# R9A09G057H register map
Vendor: Renesas Electronics; File version: 1.0
Registers are 32-bit, read-write, no defined reset value unless marked. A register's access mark holds for its fields unless they carry their own. Offsets are from the block's base; [hi:lo] are bit positions; {n}, {i} and the like mark numbered series.

## R_POEGA — IO define file for poeg.
Base 0x13001C00
Same registers: R_POEGB 0x13002000, R_POEGC 0x13002400, R_POEGD 0x13002800, R_POEGE 0x13002C00, R_POEGF 0x13003000, R_POEGG 0x13003400, R_POEGH 0x13003800
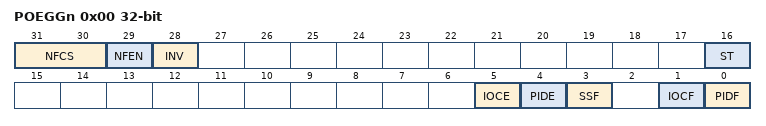
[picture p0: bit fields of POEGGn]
0x00 POEGGn
  [31:30] NFCS, [29] NFEN, [28] INV, [16] ST ro, [5] IOCE, [4] PIDE, [3] SSF, [1] IOCF, [0] PIDF

## R_RIIC0 — IO define file for riic.
Base 0x14400400
Same registers: R_RIIC8 0x11C01000, R_RIIC1 0x14400800, R_RIIC2 0x14400C00, R_RIIC3 0x14401000, R_RIIC4 0x14401400, R_RIIC5 0x14401800, R_RIIC6 0x14401C00, R_RIIC7 0x14402000
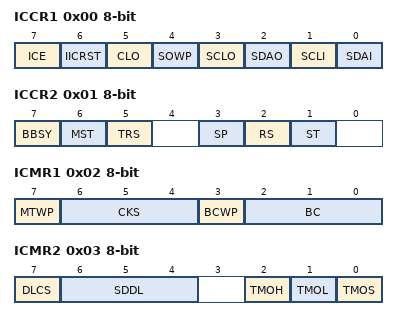
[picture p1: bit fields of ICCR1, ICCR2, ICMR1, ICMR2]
0x00 ICCR1 8-bit
  [7] ICE, [6] IICRST, [5] CLO, [4] SOWP wo, [3] SCLO, [2] SDAO, [1] SCLI ro, [0] SDAI ro
0x01 ICCR2 8-bit
  [7] BBSY ro, [6] MST, [5] TRS, [3] SP, [2] RS, [1] ST
0x02 ICMR1 8-bit
  [7] MTWP, [6:4] CKS, [3] BCWP wo, [2:0] BC
0x03 ICMR2 8-bit
  [7] DLCS, [6:4] SDDL, [2] TMOH, [1] TMOL, [0] TMOS
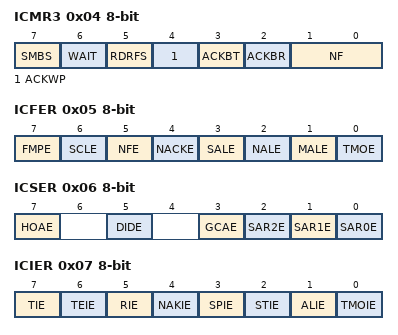
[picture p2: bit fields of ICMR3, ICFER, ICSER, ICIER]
0x04 ICMR3 8-bit
  [7] SMBS, [6] WAIT, [5] RDRFS, [4] ACKWP, [3] ACKBT, [2] ACKBR ro, [1:0] NF
0x05 ICFER 8-bit
  [7] FMPE, [6] SCLE, [5] NFE, [4] NACKE, [3] SALE, [2] NALE, [1] MALE, [0] TMOE
0x06 ICSER 8-bit
  [7] HOAE, [5] DIDE, [3] GCAE, [2] SAR2E, [1] SAR1E, [0] SAR0E
0x07 ICIER 8-bit
  [7] TIE, [6] TEIE, [5] RIE, [4] NAKIE, [3] SPIE, [2] STIE, [1] ALIE, [0] TMOIE
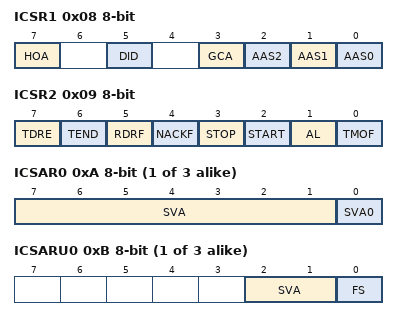
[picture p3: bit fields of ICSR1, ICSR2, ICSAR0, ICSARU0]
0x08 ICSR1 8-bit
  [7] HOA, [5] DID, [3] GCA, [2] AAS2, [1] AAS1, [0] AAS0
0x09 ICSR2 8-bit
  [7] TDRE ro, [6] TEND, [5] RDRF, [4] NACKF, [3] STOP, [2] START, [1] AL, [0] TMOF
{0xA+2i} ICSAR{i} 8-bit (i=0..2)
  [7:1] SVA, [0] SVA0
{0xB+2i} ICSARU{i} 8-bit (i=0..2)
  [2:1] SVA, [0] FS
0x10 ICBRL 8-bit
  [4:0] BRL
0x11 ICBRH 8-bit
  [4:0] BRH
0x12 ICDRT 8-bit
  [7:0] DRT
0x13 ICDRR 8-bit ro
  [7:0] DRR

## R_RTC — IO define file for rtc.
Base 0x11C00800
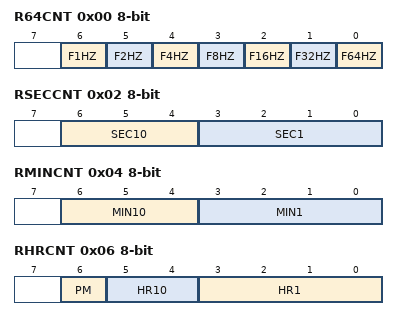
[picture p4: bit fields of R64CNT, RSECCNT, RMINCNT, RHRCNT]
0x00 R64CNT 8-bit ro
  [6] F1HZ, [5] F2HZ, [4] F4HZ, [3] F8HZ, [2] F16HZ, [1] F32HZ, [0] F64HZ
0x02 RSECCNT 8-bit
  [6:4] SEC10, [3:0] SEC1
{0x2+2i} BCNT{i} 8-bit (i=0..3)
  [7:0] BCNT
0x04 RMINCNT 8-bit
  [6:4] MIN10, [3:0] MIN1
0x06 RHRCNT 8-bit
  [6] PM, [5:4] HR10, [3:0] HR1
0x08 RWKCNT 8-bit
  [2:0] DAYW
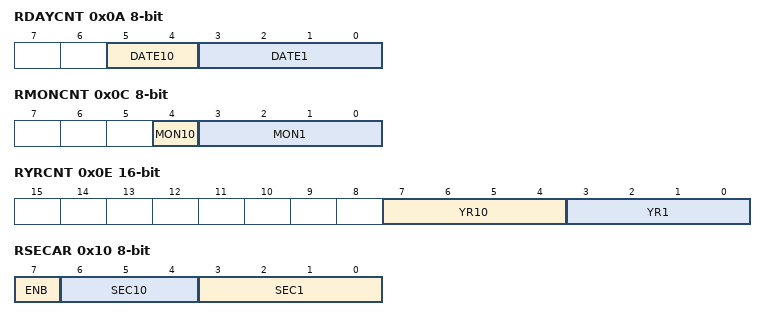
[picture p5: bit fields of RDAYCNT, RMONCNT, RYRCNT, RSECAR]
0x0A RDAYCNT 8-bit
  [5:4] DATE10, [3:0] DATE1
0x0C RMONCNT 8-bit
  [4] MON10, [3:0] MON1
0x0E RYRCNT 16-bit
  [7:4] YR10, [3:0] YR1
0x10 RSECAR 8-bit
  [7] ENB, [6:4] SEC10, [3:0] SEC1
{0x10+2i} BCNT{i}AR 8-bit (i=0..3)
  [7:0] BCNTAR
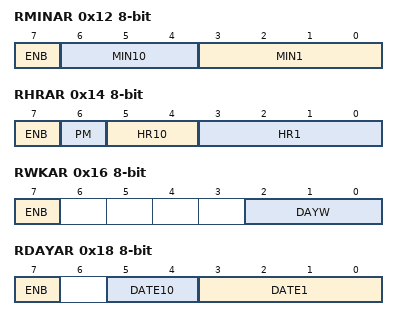
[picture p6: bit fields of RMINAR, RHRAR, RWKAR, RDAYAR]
0x12 RMINAR 8-bit
  [7] ENB, [6:4] MIN10, [3:0] MIN1
0x14 RHRAR 8-bit
  [7] ENB, [6] PM, [5:4] HR10, [3:0] HR1
0x16 RWKAR 8-bit
  [7] ENB, [2:0] DAYW
0x18 RDAYAR 8-bit
  [7] ENB, [5:4] DATE10, [3:0] DATE1
0x18 BCNT0AER 8-bit
  [7:0] ENB
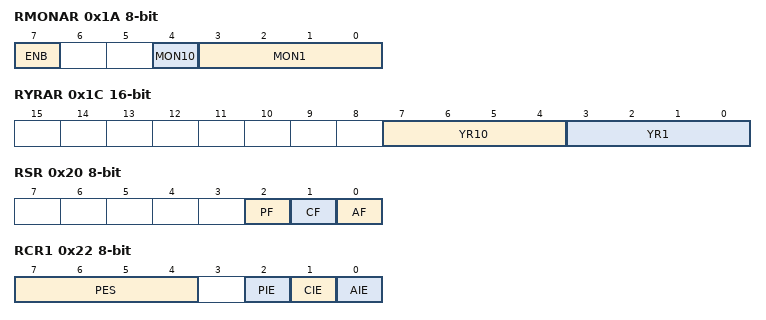
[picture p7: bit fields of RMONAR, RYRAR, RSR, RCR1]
0x1A RMONAR 8-bit
  [7] ENB, [4] MON10, [3:0] MON1
0x1A BCNT1AER 8-bit
  [7:0] ENB
0x1C RYRAR 16-bit
  [7:4] YR10, [3:0] YR1
0x1C BCNT2AER 16-bit
  [7:0] ENB
0x1E RYRAREN 8-bit
  [7] ENB
0x1E BCNT3AER 8-bit
  [7:0] ENB
0x20 RSR 8-bit
  [2] PF, [1] CF, [0] AF
0x22 RCR1 8-bit
  [7:4] PES, [2] PIE, [1] CIE, [0] AIE
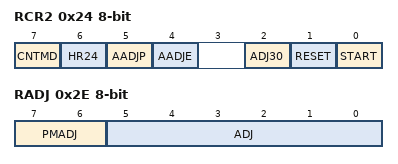
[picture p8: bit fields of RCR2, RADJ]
0x24 RCR2 8-bit
  [7] CNTMD, [6] HR24, [5] AADJP, [4] AADJE, [2] ADJ30, [1] RESET, [0] START
0x2E RADJ 8-bit
  [7:6] PMADJ, [5:0] ADJ

## R_RTC_RO — IO define file for rtc.
Base 0x11C00C00
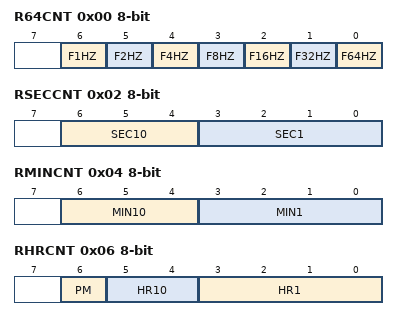
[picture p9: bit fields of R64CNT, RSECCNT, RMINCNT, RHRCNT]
0x00 R64CNT 8-bit ro
  [6] F1HZ, [5] F2HZ, [4] F4HZ, [3] F8HZ, [2] F16HZ, [1] F32HZ, [0] F64HZ
0x02 RSECCNT 8-bit ro
  [6:4] SEC10, [3:0] SEC1
{0x2+2i} BCNT{i} 8-bit ro (i=0..3)
  [7:0] BCNT
0x04 RMINCNT 8-bit ro
  [6:4] MIN10, [3:0] MIN1
0x06 RHRCNT 8-bit ro
  [6] PM, [5:4] HR10, [3:0] HR1
0x08 RWKCNT 8-bit ro
  [2:0] DAYW
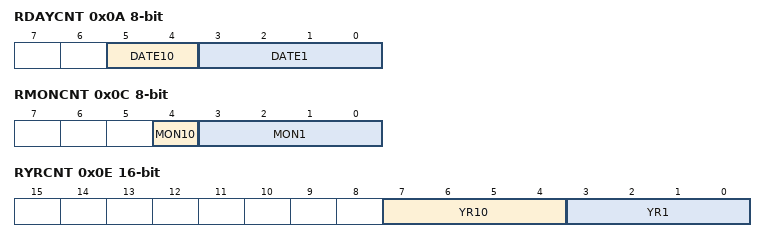
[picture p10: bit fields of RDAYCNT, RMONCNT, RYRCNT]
0x0A RDAYCNT 8-bit ro
  [5:4] DATE10, [3:0] DATE1
0x0C RMONCNT 8-bit ro
  [4] MON10, [3:0] MON1
0x0E RYRCNT 16-bit ro
  [7:4] YR10, [3:0] YR1

## R_SCI0 — IO define file for rsci.
Base 0x12800C00
Same registers: R_SCI{n} {0x12800C00+0x400*n} (n=1..9)
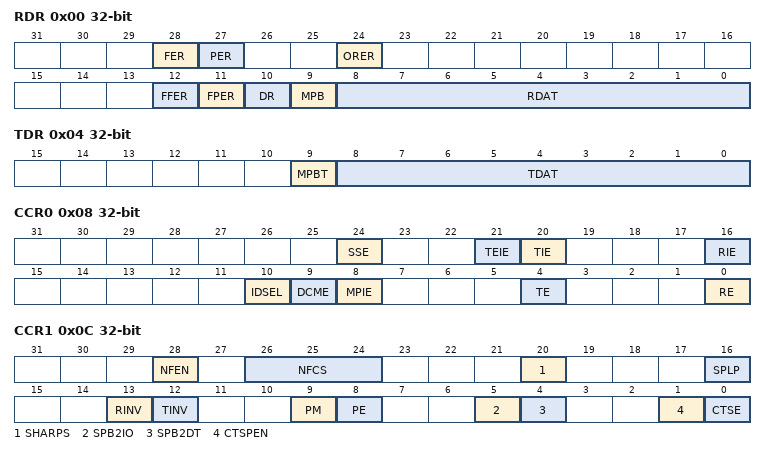
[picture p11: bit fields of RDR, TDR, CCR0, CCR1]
0x00 RDR ro
  [28] FER, [27] PER, [24] ORER, [12] FFER, [11] FPER, [10] DR, [9] MPB, [8:0] RDAT
0x00 RDR_BY 8-bit
  [7:0] RDAT
0x04 TDR
  [9] MPBT, [8:0] TDAT
0x04 TDR_BY 8-bit
  [7:0] TDAT
0x08 CCR0
  [24] SSE, [21] TEIE, [20] TIE, [16] RIE, [10] IDSEL, [9] DCME, [8] MPIE, [4] TE, [0] RE
0x0C CCR1
  [28] NFEN, [26:24] NFCS, [20] SHARPS, [16] SPLP, [13] RINV, [12] TINV, [9] PM, [8] PE, [5] SPB2IO, [4] SPB2DT, [1] CTSPEN, [0] CTSE
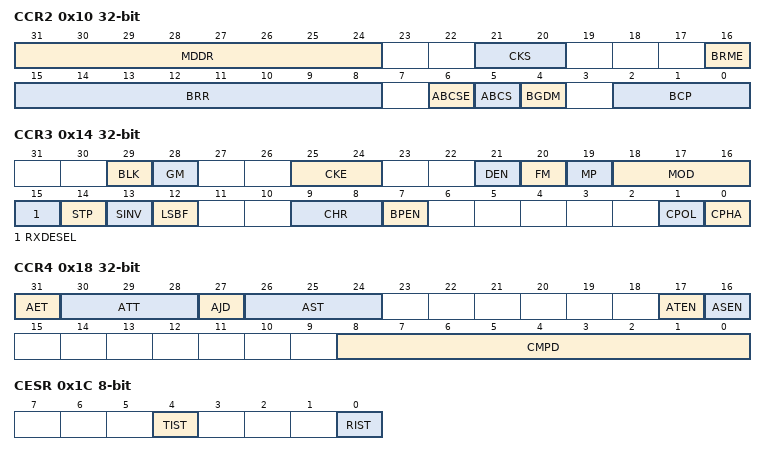
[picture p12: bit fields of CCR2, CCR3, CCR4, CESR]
0x10 CCR2
  [31:24] MDDR, [21:20] CKS, [16] BRME, [15:8] BRR, [6] ABCSE, [5] ABCS, [4] BGDM, [2:0] BCP
0x14 CCR3
  [29] BLK, [28] GM, [25:24] CKE, [21] DEN, [20] FM, [19] MP, [18:16] MOD, [15] RXDESEL, [14] STP, [13] SINV, [12] LSBF, [9:8] CHR, [7] BPEN, [1] CPOL, [0] CPHA
0x18 CCR4
  [31] AET, [30:28] ATT, [27] AJD, [26:24] AST, [17] ATEN, [16] ASEN, [8:0] CMPD
0x1C CESR 8-bit ro
  [4] TIST, [0] RIST
0x1E HCR 8-bit
  [0] HDEN
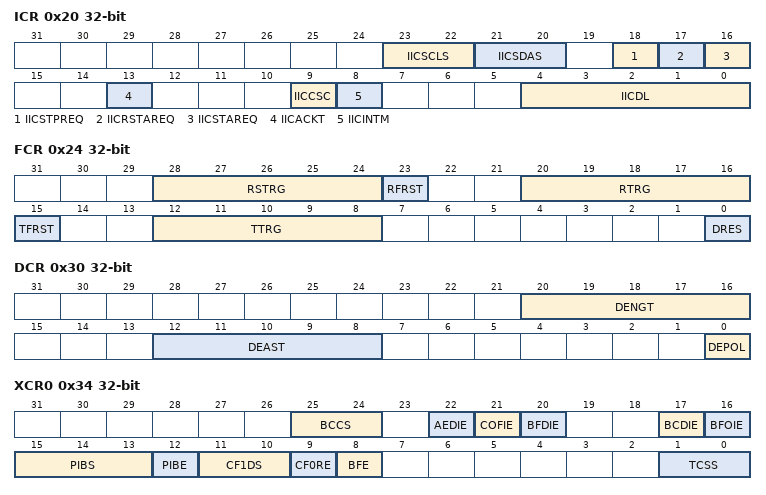
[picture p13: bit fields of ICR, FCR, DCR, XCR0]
0x20 ICR
  [23:22] IICSCLS, [21:20] IICSDAS, [18] IICSTPREQ, [17] IICRSTAREQ, [16] IICSTAREQ, [13] IICACKT, [9] IICCSC, [8] IICINTM, [4:0] IICDL
0x24 FCR
  [28:24] RSTRG, [23] RFRST wo, [20:16] RTRG, [15] TFRST wo, [12:8] TTRG, [0] DRES
0x30 DCR
  [20:16] DENGT, [12:8] DEAST, [0] DEPOL
0x34 XCR0
  [25:24] BCCS, [22] AEDIE, [21] COFIE, [20] BFDIE, [17] BCDIE, [16] BFOIE, [15:13] PIBS, [12] PIBE, [11:10] CF1DS, [9] CF0RE, [8] BFE, [1:0] TCSS
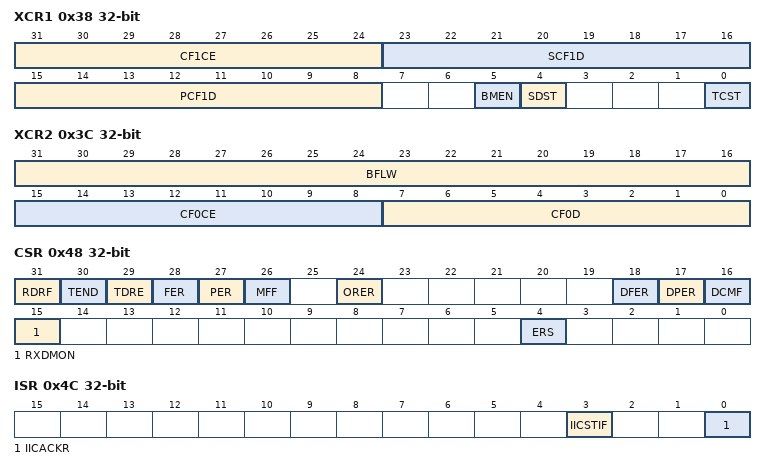
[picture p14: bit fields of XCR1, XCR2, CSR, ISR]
0x38 XCR1
  [31:24] CF1CE, [23:16] SCF1D, [15:8] PCF1D, [5] BMEN, [4] SDST, [0] TCST
0x3C XCR2
  [31:16] BFLW, [15:8] CF0CE, [7:0] CF0D
0x48 CSR ro
  [31] RDRF, [30] TEND, [29] TDRE, [28] FER, [27] PER, [26] MFF, [24] ORER, [18] DFER, [17] DPER, [16] DCMF, [15] RXDMON, [4] ERS
0x4C ISR ro
  [3] IICSTIF, [0] IICACKR
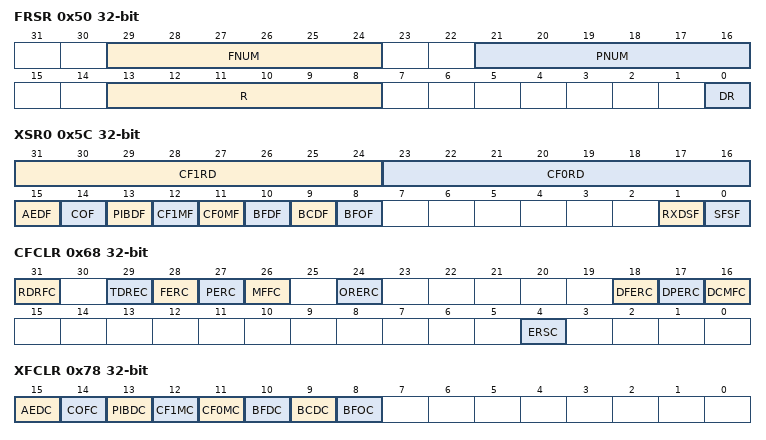
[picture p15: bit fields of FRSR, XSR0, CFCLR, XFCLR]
0x50 FRSR ro
  [29:24] FNUM, [21:16] PNUM, [13:8] R, [0] DR
0x54 FTSR ro
  [5:0] T
0x5C XSR0 ro
  [31:24] CF1RD, [23:16] CF0RD, [15] AEDF, [14] COF, [13] PIBDF, [12] CF1MF, [11] CF0MF, [10] BFDF, [9] BCDF, [8] BFOF, [1] RXDSF, [0] SFSF
0x60 XSR1 ro
  [15:0] TCNT
0x68 CFCLR wo
  [31] RDRFC, [29] TDREC, [28] FERC, [27] PERC, [26] MFFC, [24] ORERC, [18] DFERC, [17] DPERC, [16] DCMFC, [4] ERSC
0x6C ICFCLR wo
  [3] IICSTIFC
0x70 FFCLR wo
  [0] DRC
0x78 XFCLR wo
  [15] AEDC, [14] COFC, [13] PIBDC, [12] CF1MC, [11] CF0MC, [10] BFDC, [9] BCDC, [8] BFOC
